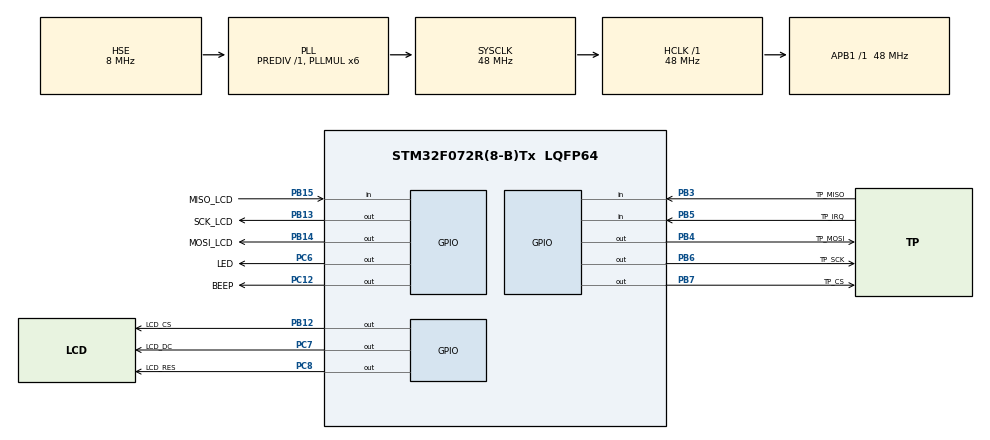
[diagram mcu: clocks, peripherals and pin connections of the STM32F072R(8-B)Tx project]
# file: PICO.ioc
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Mcu.Family=STM32F0
Mcu.Name=STM32F072R(8-B)Tx
Mcu.Package=LQFP64
PA13.Mode=Serial_Wire
PA13.Signal=SYS_SWDIO
PA14.Mode=Serial_Wire
PA14.Signal=SYS_SWCLK
PB12.GPIO_Label=LCD_CS
PB12.GPIO_Speed=GPIO_SPEED_FREQ_HIGH
PB12.PinState=GPIO_PIN_SET
PB12.Signal=GPIO_Output
PB13.GPIO_Label=SCK_LCD
PB13.GPIO_Speed=GPIO_SPEED_FREQ_HIGH
PB13.PinState=GPIO_PIN_RESET
PB13.Signal=GPIO_Output
PB14.GPIO_Label=MOSI_LCD
PB14.GPIO_Speed=GPIO_SPEED_FREQ_HIGH
PB14.Signal=GPIO_Output
PB15.GPIO_Label=MISO_LCD
PB15.Signal=GPIO_Input
PB3.GPIO_Label=TP_MISO
PB3.GPIO_PuPd=GPIO_NOPULL
PB3.Signal=GPIO_Input
PB4.GPIO_Label=TP_MOSI
PB4.GPIO_ModeDefaultOutputPP=GPIO_MODE_OUTPUT_PP
PB4.GPIO_Speed=GPIO_SPEED_FREQ_HIGH
PB4.PinState=GPIO_PIN_RESET
PB4.Signal=GPIO_Output
PB5.GPIO_Label=TP_IRQ
PB5.GPIO_PuPd=GPIO_PULLUP
PB5.Signal=GPIO_Input
PB6.GPIO_FM6=__NULL
PB6.GPIO_Label=TP_SCK
PB6.GPIO_Speed=GPIO_SPEED_FREQ_HIGH
PB6.PinState=GPIO_PIN_RESET
PB6.Signal=GPIO_Output
PB7.GPIO_Label=TP_CS
PB7.GPIO_Speed=GPIO_SPEED_FREQ_HIGH
PB7.PinState=GPIO_PIN_SET
PB7.Signal=GPIO_Output
PC12.GPIO_Label=BEEP
PC12.GPIO_Speed=GPIO_SPEED_FREQ_HIGH
PC12.PinState=GPIO_PIN_RESET
PC12.Signal=GPIO_Output
PC14-OSC32_IN.Mode=LSE-External-Oscillator
PC14-OSC32_IN.Signal=RCC_OSC32_IN
PC15-OSC32_OUT.Mode=LSE-External-Oscillator
PC15-OSC32_OUT.Signal=RCC_OSC32_OUT
PC6.GPIO_Label=LED
PC6.GPIO_Speed=GPIO_SPEED_FREQ_HIGH
PC6.PinState=GPIO_PIN_RESET
PC6.Signal=GPIO_Output
PC7.GPIO_Label=LCD_DC
PC7.GPIO_Speed=GPIO_SPEED_FREQ_HIGH
PC7.PinState=GPIO_PIN_RESET
PC7.Signal=GPIO_Output
PC8.GPIO_Label=LCD_RES
PC8.GPIO_Speed=GPIO_SPEED_FREQ_HIGH
PC8.PinState=GPIO_PIN_RESET
PC8.Signal=GPIO_Output
PF0-OSC_IN.Mode=HSE-External-Oscillator
PF0-OSC_IN.Signal=RCC_OSC_IN
PF1-OSC_OUT.Mode=HSE-External-Oscillator
PF1-OSC_OUT.Signal=RCC_OSC_OUT
ProjectManager.HeapSize=0x200
ProjectManager.StackSize=0x400
ProjectManager.TargetToolchain=MDK-ARM V5.32
RCC.AHBFreq_Value=48000000
RCC.APB1Freq_Value=48000000
RCC.APB1TimFreq_Value=48000000
RCC.HCLKFreq_Value=48000000
RCC.PLLMUL=RCC_PLL_MUL6
RCC.PLLSourceVirtual=RCC_PLLSOURCE_HSE
RCC.SYSCLKFreq_VALUE=48000000
RCC.SYSCLKSource=RCC_SYSCLKSOURCE_PLLCLK
board=custom

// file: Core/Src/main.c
/* USER CODE BEGIN Header */
/**
 ******************************************************************************
 * @file           : main.c
 * @brief          : Main program body
 ******************************************************************************
 * @attention
 *
 * Copyright (c) 2025 STMicroelectronics.
 * All rights reserved.
 *
 * This software is licensed under terms that can be found in the LICENSE file
 * in the root directory of this software component.
 * If no LICENSE file comes with this software, it is provided AS-IS.
 *
 ******************************************************************************
 */
/* USER CODE END Header */
#include "main.h"
#include "gpio.h"

/* USER CODE BEGIN Includes */
#include "lcd.h"
#include "touch.h"
#include "delay.h"
/* USER CODE END Includes */

void SystemClock_Config(void);

int main(void)
{

  /* MCU Configuration--------------------------------------------------------*/

  /* Reset of all peripherals, Initializes the Flash interface and the Systick. */
  HAL_Init();

  /* Configure the system clock */
  SystemClock_Config();

  /* Initialize all configured peripherals */
  MX_GPIO_Init();
  TIM14_Init();
  /* USER CODE BEGIN 2 */
  LCD_Init();
  LCD_Clear(LCD_BACKGROUNDCOLOR);
  uint16_t xval, yval;
  // tp_dev.init();
  /* USER CODE END 2 */

  /* Infinite loop */
  while (1)
  {

    /* USER CODE BEGIN 3 */
    xval = TP_Read_AD(0xD0);
    yval = TP_Read_AD(0x90);

    LCD_Show_Num(30, 40, xval, 6, 16, 0x07E0);
    LCD_Show_Num(30, 80, yval, 6, 16, 0x07E0);
    HAL_Delay(3000);
    LCD_Clear(0xFFFF);
  }
  /* USER CODE END 3 */
}

void SystemClock_Config(void)
{
  RCC_OscInitTypeDef RCC_OscInitStruct = {0};
  RCC_ClkInitTypeDef RCC_ClkInitStruct = {0};

  /** Initializes the RCC Oscillators according to the specified parameters
   * in the RCC_OscInitTypeDef structure.
   */
  RCC_OscInitStruct.OscillatorType = RCC_OSCILLATORTYPE_HSE;
  RCC_OscInitStruct.HSEState = RCC_HSE_ON;
  RCC_OscInitStruct.PLL.PLLState = RCC_PLL_ON;
  RCC_OscInitStruct.PLL.PLLSource = RCC_PLLSOURCE_HSE;
  RCC_OscInitStruct.PLL.PLLMUL = RCC_PLL_MUL6;
  RCC_OscInitStruct.PLL.PREDIV = RCC_PREDIV_DIV1;
  if (HAL_RCC_OscConfig(&RCC_OscInitStruct) != HAL_OK)
  {
    Error_Handler();
  }

  /** Initializes the CPU, AHB and APB buses clocks
   */
  RCC_ClkInitStruct.ClockType = RCC_CLOCKTYPE_HCLK | RCC_CLOCKTYPE_SYSCLK | RCC_CLOCKTYPE_PCLK1;
  RCC_ClkInitStruct.SYSCLKSource = RCC_SYSCLKSOURCE_PLLCLK;
  RCC_ClkInitStruct.AHBCLKDivider = RCC_SYSCLK_DIV1;
  RCC_ClkInitStruct.APB1CLKDivider = RCC_HCLK_DIV1;

  if (HAL_RCC_ClockConfig(&RCC_ClkInitStruct, FLASH_LATENCY_1) != HAL_OK)
  {
    Error_Handler();
  }
}

void Error_Handler(void)
{
  __disable_irq();
  while (1)
  {
  }
}
